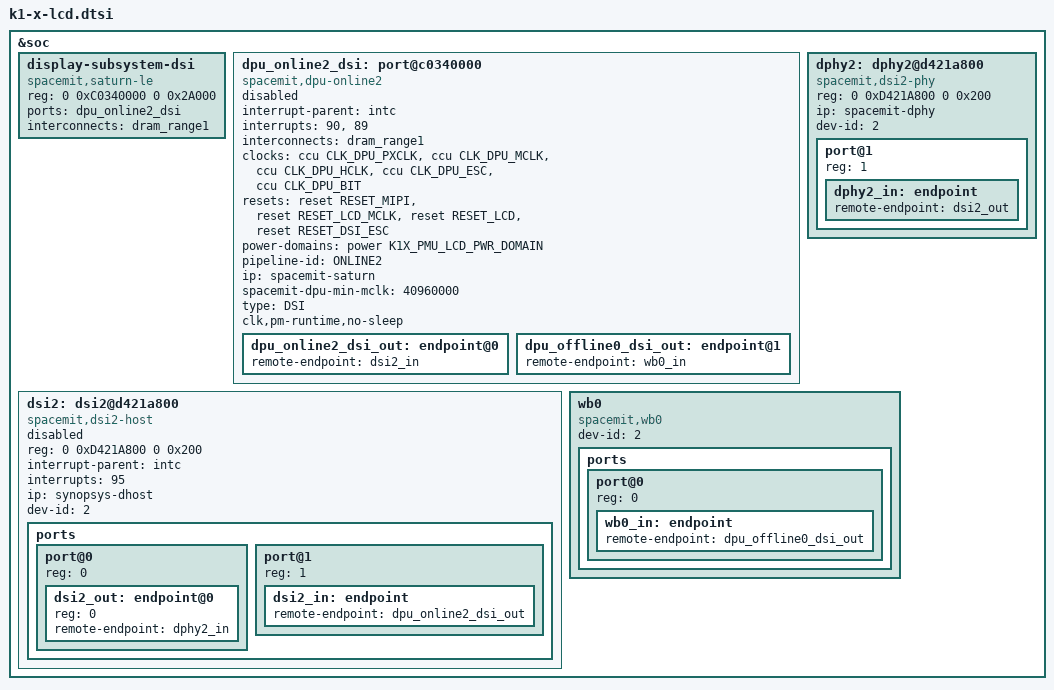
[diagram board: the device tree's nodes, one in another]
// SPDX-License-Identifier: (GPL-2.0 OR MIT)
/* Copyright (c) 2023 Spacemit, Inc */

&soc {
	display-subsystem-dsi {
		compatible = "spacemit,saturn-le";
		reg = <0 0xC0340000 0 0x2A000>;
		ports = <&dpu_online2_dsi>;
		interconnects = <&dram_range1>;
		interconnect-names = "dma-mem";
	};

	dpu_online2_dsi: port@c0340000 {
		compatible = "spacemit,dpu-online2";
		interrupt-parent = <&intc>;
		interrupts = <90>, <89>;
		interrupt-names = "ONLINE_IRQ", "OFFLINE_IRQ";
		interconnects = <&dram_range1>;
		interconnect-names = "dma-mem";
		clocks = <&ccu CLK_DPU_PXCLK>,
			<&ccu CLK_DPU_MCLK>,
			<&ccu CLK_DPU_HCLK>,
			<&ccu CLK_DPU_ESC>,
			<&ccu CLK_DPU_BIT>;
		clock-names = "pxclk", "mclk", "hclk", "escclk", "bitclk";
		resets = <&reset RESET_MIPI>,
			<&reset RESET_LCD_MCLK>,
			<&reset RESET_LCD>,
			<&reset RESET_DSI_ESC>;
		reset-names= "dsi_reset", "mclk_reset", "lcd_reset","esc_reset";
		power-domains = <&power K1X_PMU_LCD_PWR_DOMAIN>;
		pipeline-id = <ONLINE2>;
		ip = "spacemit-saturn";
		spacemit-dpu-min-mclk = <40960000>;
		type = <DSI>;
		clk,pm-runtime,no-sleep;
		status = "disabled";

		dpu_online2_dsi_out: endpoint@0 {
			remote-endpoint = <&dsi2_in>;
		};

		dpu_offline0_dsi_out: endpoint@1 {
			remote-endpoint = <&wb0_in>;
		};
	};

	dsi2: dsi2@d421a800 {
		compatible = "spacemit,dsi2-host";
		#address-cells = <1>;
		#size-cells = <0>;
		reg = <0 0xD421A800 0 0x200>;
		interrupt-parent = <&intc>;
		interrupts = <95>;
		ip = "synopsys-dhost";
		dev-id = <2>;
		status = "disabled";

		ports {
			#address-cells = <1>;
			#size-cells = <0>;

			port@0 {
				reg = <0>;
				#address-cells = <1>;
				#size-cells = <0>;

				dsi2_out: endpoint@0 {
					reg = <0>;
					remote-endpoint = <&dphy2_in>;
				};
			};

			port@1 {
				reg = <1>;
				dsi2_in: endpoint {
					remote-endpoint = <&dpu_online2_dsi_out>;
				};
			};
		};
	};

	dphy2: dphy2@d421a800 {
		compatible = "spacemit,dsi2-phy";
		#address-cells = <1>;
		#size-cells = <0>;
		reg = <0 0xD421A800 0 0x200>;
		ip = "spacemit-dphy";
		dev-id = <2>;
		status = "okay";

		port@1 {
			reg = <1>;
			dphy2_in: endpoint {
				remote-endpoint = <&dsi2_out>;
			};
		};
	};

	wb0 {
		compatible = "spacemit,wb0";
		dev-id = <2>;
		status = "okay";

		ports {
			#address-cells = <1>;
			#size-cells = <0>;
			port@0 {
				reg = <0>;
				wb0_in: endpoint {
					remote-endpoint = <&dpu_offline0_dsi_out>;
				};
			};
		};
	};
};
